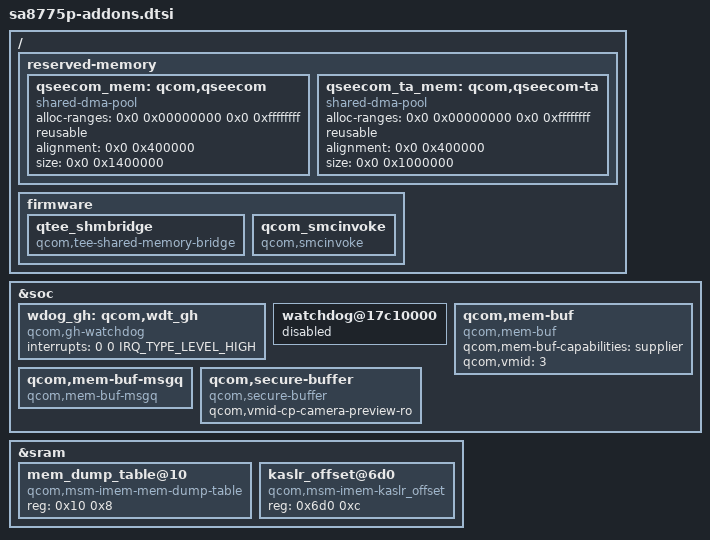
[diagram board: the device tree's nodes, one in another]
// SPDX-License-Identifier: BSD-3-Clause
/*
 * Copyright (c) 2024 Qualcomm Innovation Center, Inc. All rights reserved.
 */

#include "sa8775p-dma-heaps.dtsi"

/ {
	reserved-memory {
		qseecom_mem: qcom,qseecom {
			compatible = "shared-dma-pool";
			alloc-ranges = <0x0 0x00000000 0x0 0xffffffff>;
			reusable;
			alignment = <0x0 0x400000>;
			size = <0x0 0x1400000>; /* 20M */
		};

		qseecom_ta_mem: qcom,qseecom-ta {
			compatible = "shared-dma-pool";
			alloc-ranges = <0x0 0x00000000 0x0 0xffffffff>;
			reusable;
			alignment = <0x0 0x400000>;
			size = <0x0 0x1000000>; /* 16M */
		};
	};

	firmware {
		qtee_shmbridge {
			compatible = "qcom,tee-shared-memory-bridge";
		};

		qcom_smcinvoke {
			compatible = "qcom,smcinvoke";
		};
	};

};

&soc {
	wdog_gh: qcom,wdt_gh {
		compatible = "qcom,gh-watchdog";
		interrupts = <0 0 IRQ_TYPE_LEVEL_HIGH>;
	};

	watchdog@17c10000 {
		status = "disabled";
	};
};

&sram {
	mem_dump_table@10 {
		compatible = "qcom,msm-imem-mem-dump-table";
		reg = <0x10 0x8>;
	};

	kaslr_offset@6d0 {
		compatible = "qcom,msm-imem-kaslr_offset";
		reg = <0x6d0 0xc>;
	};
};

&soc {
	qcom,mem-buf {
		compatible = "qcom,mem-buf";
		qcom,mem-buf-capabilities = "supplier";
		qcom,vmid = <3>;
	};

	qcom,mem-buf-msgq {
		compatible = "qcom,mem-buf-msgq";
	};

	qcom,secure-buffer {
		compatible = "qcom,secure-buffer";
		qcom,vmid-cp-camera-preview-ro;
	};
};
